# LRFDMDM register map
Vendor: Texas Instruments
Registers are 32-bit, access per field, reset 0x0 unless marked. A register's access mark holds for its fields unless they carry their own. Offsets are as the file gives them; [hi:lo] are bit positions; {n}, {i} and the like mark numbered series; 'fields as' and 'values as' point back to an identical list.

## LRFDMDM (part 2 of 2)
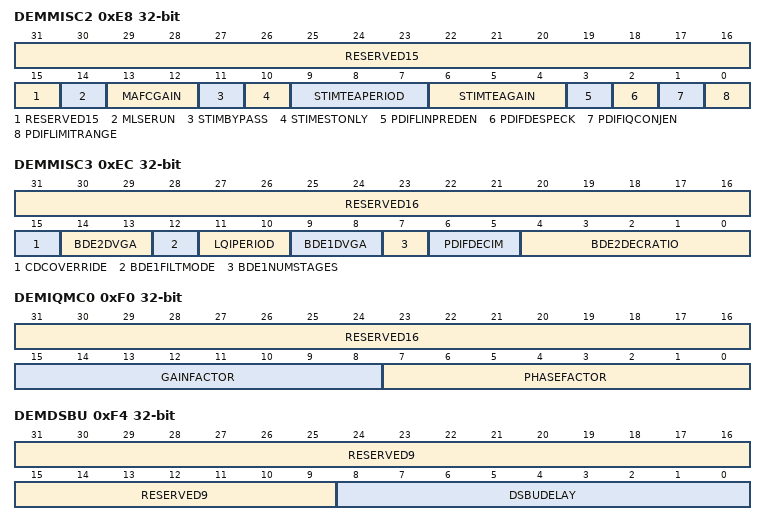
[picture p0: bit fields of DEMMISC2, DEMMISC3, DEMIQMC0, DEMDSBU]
0xE8 DEMMISC2 — Internal. Only to be used through TI provided API.
  [31:15] RESERVED15 ro — Internal. Only to be used through TI provided API.
  [14] MLSERUN rw — Internal. Only to be used through TI provided API.
    1=EN (Internal. Only to be used through TI provided API.); 0=DIS (Internal. Only to be used through TI provided API.)
  [13:12] MAFCGAIN rw — Internal. Only to be used through TI provided API.
    3=ALLONES (Internal. Only to be used through TI provided API.); 0=ALLZEROS (Internal. Only to be used through TI provided API.)
  [11] STIMBYPASS rw — Internal. Only to be used through TI provided API.
    values as MLSERUN
  [10] STIMESTONLY rw — Internal. Only to be used through TI provided API.
    values as MLSERUN
  [9:7] STIMTEAPERIOD rw — Internal. Only to be used through TI provided API.
    5=SYM128 (Internal. Only to be used through TI provided API.); 4=SYM64 (Internal. Only to be used through TI provided API.); 3=SYM32 (Internal. Only to be used through TI provided API.); 2=SYM16 (Internal. Only to be used through TI provided API.); 1=SYM8 (Internal. Only to be used through TI provided API.); 0=SYM4 (Internal. Only to be used through TI provided API.)
  [6:4] STIMTEAGAIN rw — Internal. Only to be used through TI provided API.
    7=DIV4 (Internal. Only to be used through TI provided API.); 6=DIV8 (Internal. Only to be used through TI provided API.); 5=DIV16 (Internal. Only to be used through TI provided API.); 4=DIV32 (Internal. Only to be used through TI provided API.); 3=DIV64 (Internal. Only to be used through TI provided API.); 2=DIV128 (Internal. Only to be used through TI provided API.); 1=DIV256 (Internal. Only to be used through TI provided API.); 0=DIV512 (Internal. Only to be used through TI provided API.)
  [3] PDIFLINPREDEN rw — Internal. Only to be used through TI provided API.
    1=ON (Internal. Only to be used through TI provided API.); 0=OFF (Internal. Only to be used through TI provided API.)
  [2] PDIFDESPECK rw — Internal. Only to be used through TI provided API.
    values as MLSERUN
  [1] PDIFIQCONJEN rw — Internal. Only to be used through TI provided API.
    values as PDIFLINPREDEN
  [0] PDIFLIMITRANGE rw — Internal. Only to be used through TI provided API.
    values as MLSERUN
0xEC DEMMISC3 — Internal. Only to be used through TI provided API.
  [31:16] RESERVED16 ro — Internal. Only to be used through TI provided API.
  [15] CDCOVERRIDE rw — Internal. Only to be used through TI provided API.
  [14:13] BDE2DVGA rw — Internal. Only to be used through TI provided API.
    3=GAIN8 (Internal. Only to be used through TI provided API.); 2=GAIN4 (Internal. Only to be used through TI provided API.); 1=GAIN2 (Internal. Only to be used through TI provided API.); 0=GAIN1 (Internal. Only to be used through TI provided API.)
  [12] BDE1FILTMODE rw — Internal. Only to be used through TI provided API.
    1=DIV2 (Internal. Only to be used through TI provided API.); 0=DIV1 (Internal. Only to be used through TI provided API.)
  [11:10] LQIPERIOD rw — Internal. Only to be used through TI provided API.
    3=SYM1024 (Internal. Only to be used through TI provided API.); 2=SYM256 (Internal. Only to be used through TI provided API.); 1=SYM64 (Internal. Only to be used through TI provided API.); 0=SYM16 (Internal. Only to be used through TI provided API.)
  [9:8] BDE1DVGA rw — Internal. Only to be used through TI provided API.
    values as BDE2DVGA
  [7] BDE1NUMSTAGES rw — Internal. Only to be used through TI provided API.
    values as BDE1FILTMODE
  [6:5] PDIFDECIM rw — Internal. Only to be used through TI provided API.
    2=DIV4 (Internal. Only to be used through TI provided API.); 1=DIV2 (Internal. Only to be used through TI provided API.); 0=DIV1 (Internal. Only to be used through TI provided API.)
  [4:0] BDE2DECRATIO rw — Internal. Only to be used through TI provided API.
    3=DIV8 (Internal. Only to be used through TI provided API.); 2=DIV4 (Internal. Only to be used through TI provided API.); 1=DIV2 (Internal. Only to be used through TI provided API.); 0=DIV1 (Internal. Only to be used through TI provided API.)
0xF0 DEMIQMC0 — Internal. Only to be used through TI provided API.
  [31:16] RESERVED16 ro — Internal. Only to be used through TI provided API.
  [15:8] GAINFACTOR rw — Internal. Only to be used through TI provided API.
    255=ALLONES (Internal. Only to be used through TI provided API.); 0=ALLZEROS (Internal. Only to be used through TI provided API.)
  [7:0] PHASEFACTOR rw — Internal. Only to be used through TI provided API.
    values as GAINFACTOR
0xF4 DEMDSBU — Internal. Only to be used through TI provided API.
  [31:9] RESERVED9 ro — Internal. Only to be used through TI provided API.
  [8:0] DSBUDELAY rw — Internal. Only to be used through TI provided API.
    values as DEMIQMC0.GAINFACTOR
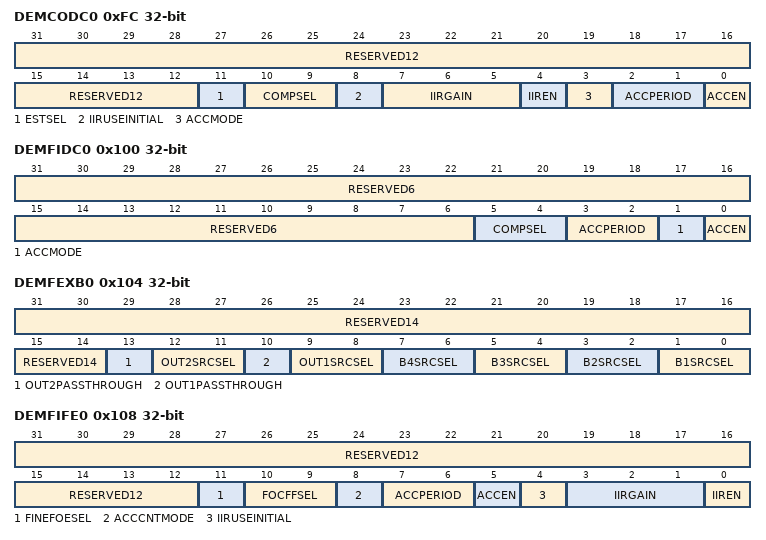
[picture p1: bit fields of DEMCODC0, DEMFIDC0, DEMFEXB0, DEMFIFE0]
0xFC DEMCODC0 — Internal. Only to be used through TI provided API.
  [31:12] RESERVED12 ro — Internal. Only to be used through TI provided API.
  [11] ESTSEL rw — Internal. Only to be used through TI provided API.
    1=IIR (Internal. Only to be used through TI provided API.); 0=ACC (Internal. Only to be used through TI provided API.)
  [10:9] COMPSEL rw — Internal. Only to be used through TI provided API.
    3=IIR (Internal. Only to be used through TI provided API.); 2=ACC (Internal. Only to be used through TI provided API.); 0=MANUAL (Internal. Only to be used through TI provided API.)
  [8] IIRUSEINITIAL rw — Internal. Only to be used through TI provided API.
    values as DEMMISC2.MLSERUN
  [7:5] IIRGAIN rw — Internal. Only to be used through TI provided API.
    7=DIV1024 (Internal. Only to be used through TI provided API.); 6=DIV512 (Internal. Only to be used through TI provided API.); 5=DIV256 (Internal. Only to be used through TI provided API.); 4=DIV128 (Internal. Only to be used through TI provided API.); 3=DIV64 (Internal. Only to be used through TI provided API.); 2=DIV32 (Internal. Only to be used through TI provided API.); 1=DIV16 (Internal. Only to be used through TI provided API.); 0=OFF (Internal. Only to be used through TI provided API.)
  [4] IIREN rw — Internal. Only to be used through TI provided API.
    values as DEMMISC2.PDIFLINPREDEN
  [3] ACCMODE rw — Internal. Only to be used through TI provided API.
    1=CONT (Internal. Only to be used through TI provided API.); 0=SINGLE (Internal. Only to be used through TI provided API.)
  [2:1] ACCPERIOD rw — Internal. Only to be used through TI provided API.
    3=SMPL512 (Internal. Only to be used through TI provided API.); 2=SMPL128 (Internal. Only to be used through TI provided API.); 1=SMPL32 (Internal. Only to be used through TI provided API.); 0=SMPL8 (Internal. Only to be used through TI provided API.)
  [0] ACCEN rw — Internal. Only to be used through TI provided API.
    values as DEMMISC2.PDIFLINPREDEN
0x100 DEMFIDC0 — Internal. Only to be used through TI provided API.
  [31:6] RESERVED6 ro — Internal. Only to be used through TI provided API.
  [5:4] COMPSEL rw — Internal. Only to be used through TI provided API.
    2=ACC (Internal. Only to be used through TI provided API.); 0=MANUAL (Internal. Only to be used through TI provided API.)
  [3:2] ACCPERIOD rw — Internal. Only to be used through TI provided API.
    values as DEMCODC0.ACCPERIOD
  [1] ACCMODE rw — Internal. Only to be used through TI provided API.
    values as DEMCODC0.ACCMODE
  [0] ACCEN rw — Internal. Only to be used through TI provided API.
    values as DEMMISC2.PDIFLINPREDEN
0x104 DEMFEXB0 — Internal. Only to be used through TI provided API.
  [31:14] RESERVED14 ro — Internal. Only to be used through TI provided API.
  [13] OUT2PASSTHROUGH rw — Internal. Only to be used through TI provided API.
    1=ONE (Internal. Only to be used through TI provided API.); 0=ZERO (Internal. Only to be used through TI provided API.)
  [12:11] OUT2SRCSEL rw — Internal. Only to be used through TI provided API.
    2=BDE1 (Internal. Only to be used through TI provided API.); 1=CMIX (Internal. Only to be used through TI provided API.); 0=CODC (Internal. Only to be used through TI provided API.)
  [10] OUT1PASSTHROUGH rw — Internal. Only to be used through TI provided API.
    values as OUT2PASSTHROUGH
  [9:8] OUT1SRCSEL rw — Internal. Only to be used through TI provided API.
    values as OUT2SRCSEL
  [7:6] B4SRCSEL rw — Internal. Only to be used through TI provided API.
    3=ONES (Internal. Only to be used through TI provided API.); 0=ZEROS (Internal. Only to be used through TI provided API.)
  [5:4] B3SRCSEL rw — Internal. Only to be used through TI provided API.
    2=CMIX (Internal. Only to be used through TI provided API.); 1=CODC (Internal. Only to be used through TI provided API.); 0=INPUT (Internal. Only to be used through TI provided API.)
  [3:2] B2SRCSEL rw — Internal. Only to be used through TI provided API.
    2=BDE1 (Internal. Only to be used through TI provided API.); 1=CODC (Internal. Only to be used through TI provided API.); 0=INPUT (Internal. Only to be used through TI provided API.)
  [1:0] B1SRCSEL rw — Internal. Only to be used through TI provided API.
    2=BDE1 (Internal. Only to be used through TI provided API.); 1=CMIX (Internal. Only to be used through TI provided API.); 0=INPUT (Internal. Only to be used through TI provided API.)
0x108 DEMFIFE0 — Internal. Only to be used through TI provided API.
  [31:12] RESERVED12 ro — Internal. Only to be used through TI provided API.
  [11] FINEFOESEL rw — Internal. Only to be used through TI provided API.
    1=ACC (Internal. Only to be used through TI provided API.); 0=IIR (Internal. Only to be used through TI provided API.)
  [10:9] FOCFFSEL rw — Internal. Only to be used through TI provided API.
    2=MANUAL (Internal. Only to be used through TI provided API.); 1=ACC (Internal. Only to be used through TI provided API.); 0=IIR (Internal. Only to be used through TI provided API.)
  [8] ACCCNTMODE rw — Internal. Only to be used through TI provided API.
    values as DEMCODC0.ACCMODE
  [7:6] ACCPERIOD rw — Internal. Only to be used through TI provided API.
    3=PER512 (Internal. Only to be used through TI provided API.); 2=PER256 (Internal. Only to be used through TI provided API.); 1=PER128 (Internal. Only to be used through TI provided API.); 0=PER64 (Internal. Only to be used through TI provided API.)
  [5] ACCEN rw — Internal. Only to be used through TI provided API.
    values as DEMMISC2.PDIFLINPREDEN
  [4] IIRUSEINITIAL rw — Internal. Only to be used through TI provided API.
    values as DEMMISC2.MLSERUN
  [3:1] IIRGAIN rw — Internal. Only to be used through TI provided API.
    values as DEMCODC0.IIRGAIN
  [0] IIREN rw — Internal. Only to be used through TI provided API.
    values as DEMMISC2.PDIFLINPREDEN
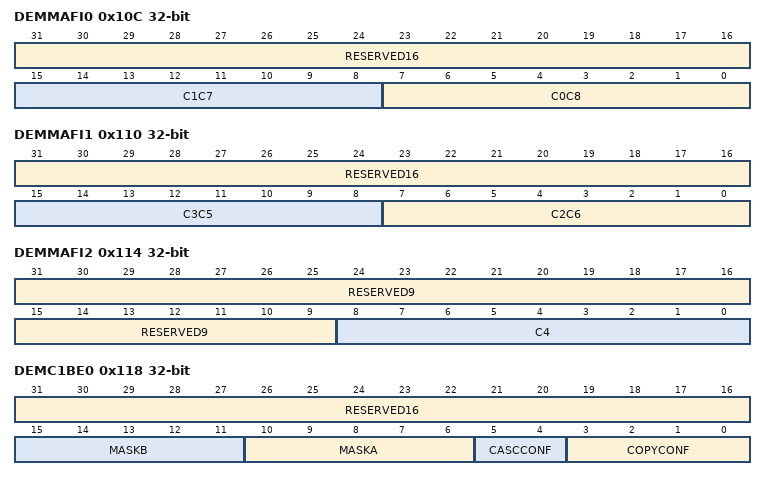
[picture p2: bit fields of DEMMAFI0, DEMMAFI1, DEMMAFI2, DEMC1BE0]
0x10C DEMMAFI0 — Internal. Only to be used through TI provided API.
  [31:16] RESERVED16 ro — Internal. Only to be used through TI provided API.
  [15:8] C1C7 rw — Internal. Only to be used through TI provided API.
    values as DEMIQMC0.GAINFACTOR
  [7:0] C0C8 rw — Internal. Only to be used through TI provided API.
    values as DEMIQMC0.GAINFACTOR
0x110 DEMMAFI1 — Internal. Only to be used through TI provided API.
  [31:16] RESERVED16 ro — Internal. Only to be used through TI provided API.
  [15:8] C3C5 rw — Internal. Only to be used through TI provided API.
    values as DEMIQMC0.GAINFACTOR
  [7:0] C2C6 rw — Internal. Only to be used through TI provided API.
    values as DEMIQMC0.GAINFACTOR
0x114 DEMMAFI2 — Internal. Only to be used through TI provided API.
  [31:9] RESERVED9 ro — Internal. Only to be used through TI provided API.
  [8:0] C4 rw — Internal. Only to be used through TI provided API.
    0x1FF=ALLONES (Internal. Only to be used through TI provided API.); 0=ALLZEROS (Internal. Only to be used through TI provided API.)
0x118 DEMC1BE0 — Internal. Only to be used through TI provided API.
  [31:16] RESERVED16 ro — Internal. Only to be used through TI provided API.
  [15:11] MASKB rw — Internal. Only to be used through TI provided API.
    31=ALLONES (Internal. Only to be used through TI provided API.); 0=ALLZEROS (Internal. Only to be used through TI provided API.)
  [10:6] MASKA rw — Internal. Only to be used through TI provided API.
    values as MASKB
  [5:4] CASCCONF rw — Internal. Only to be used through TI provided API.
    2=PARALLEL (Internal. Only to be used through TI provided API.); 1=SERIAL (Internal. Only to be used through TI provided API.); 0=SINGLE (Internal. Only to be used through TI provided API.)
  [3:0] COPYCONF rw — Internal. Only to be used through TI provided API.
    15=ALLONES (Internal. Only to be used through TI provided API.); 0=ALLZEROS (Internal. Only to be used through TI provided API.)
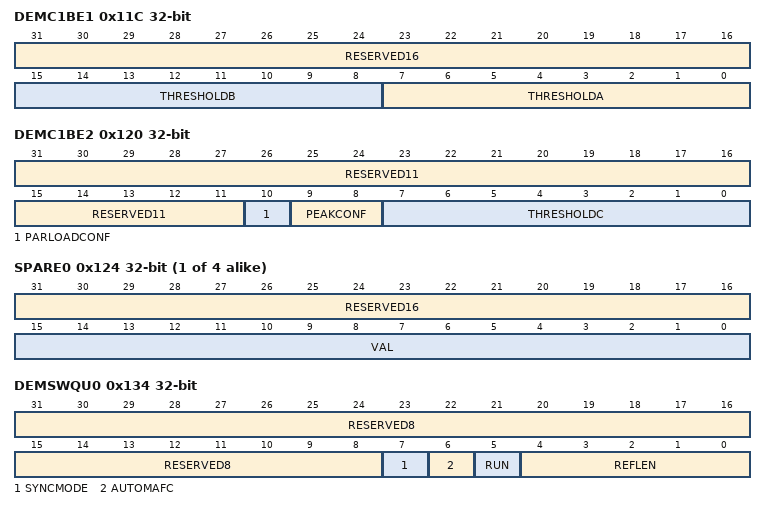
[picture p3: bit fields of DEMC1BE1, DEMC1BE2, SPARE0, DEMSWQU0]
0x11C DEMC1BE1 — Internal. Only to be used through TI provided API.
  [31:16] RESERVED16 ro — Internal. Only to be used through TI provided API.
  [15:8] THRESHOLDB rw — Internal. Only to be used through TI provided API.
    values as DEMIQMC0.GAINFACTOR
  [7:0] THRESHOLDA rw — Internal. Only to be used through TI provided API.
    values as DEMIQMC0.GAINFACTOR
0x120 DEMC1BE2 — Internal. Only to be used through TI provided API.
  [31:11] RESERVED11 ro — Internal. Only to be used through TI provided API.
  [10] PARLOADCONF rw — Internal. Only to be used through TI provided API.
    1=ATOD (Internal. Only to be used through TI provided API.); 0=ATOB (Internal. Only to be used through TI provided API.)
  [9:8] PEAKCONF rw — Internal. Only to be used through TI provided API.
    2=BESTAB (Internal. Only to be used through TI provided API.); 1=BEST (Internal. Only to be used through TI provided API.); 0=THRESH (Internal. Only to be used through TI provided API.)
  [7:0] THRESHOLDC rw — Internal. Only to be used through TI provided API.
    values as DEMIQMC0.GAINFACTOR
{0x124+4i} SPARE{i} (i=0..3) — Internal. Only to be used through TI provided API.
  [31:16] RESERVED16 ro — Internal. Only to be used through TI provided API.
  [15:0] VAL rw — Internal. Only to be used through TI provided API.
    0xFFFF=ALLONES (Internal. Only to be used through TI provided API.); 0=ALLZEROS (Internal. Only to be used through TI provided API.)
0x134 DEMSWQU0 — Internal. Only to be used through TI provided API.
  [31:8] RESERVED8 ro — Internal. Only to be used through TI provided API.
  [7] SYNCMODE rw — Internal. Only to be used through TI provided API.
    values as DEMFEXB0.OUT2PASSTHROUGH
  [6] AUTOMAFC rw — Internal. Only to be used through TI provided API.
    values as DEMMISC2.PDIFLINPREDEN
  [5] RUN rw — Internal. Only to be used through TI provided API.
    values as DEMMISC2.PDIFLINPREDEN
  [4:0] REFLEN rw — Internal. Only to be used through TI provided API.
    values as DEMC1BE0.MASKB
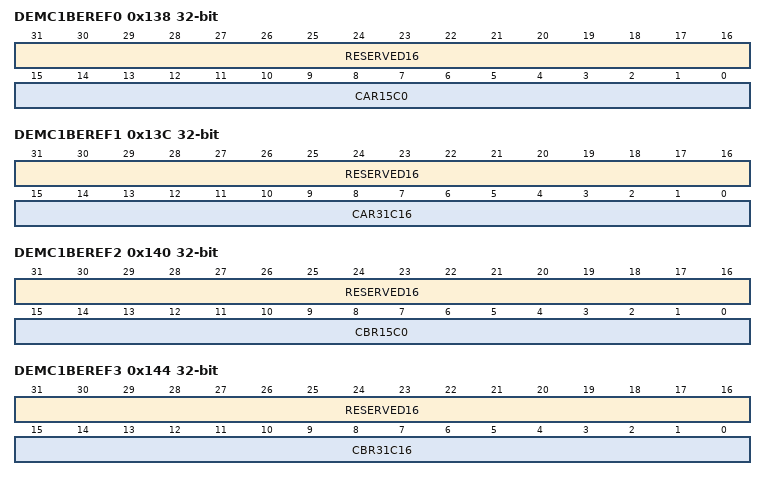
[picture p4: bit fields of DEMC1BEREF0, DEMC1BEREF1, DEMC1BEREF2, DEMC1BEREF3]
0x138 DEMC1BEREF0 — Internal. Only to be used through TI provided API.
  [31:16] RESERVED16 ro — Internal. Only to be used through TI provided API.
  [15:0] CAR15C0 rw — Internal. Only to be used through TI provided API.
    values as SPARE0.VAL
0x13C DEMC1BEREF1 — Internal. Only to be used through TI provided API.
  [31:16] RESERVED16 ro — Internal. Only to be used through TI provided API.
  [15:0] CAR31C16 rw — Internal. Only to be used through TI provided API.
    values as SPARE0.VAL
0x140 DEMC1BEREF2 — Internal. Only to be used through TI provided API.
  [31:16] RESERVED16 ro — Internal. Only to be used through TI provided API.
  [15:0] CBR15C0 rw — Internal. Only to be used through TI provided API.
    values as SPARE0.VAL
0x144 DEMC1BEREF3 — Internal. Only to be used through TI provided API.
  [31:16] RESERVED16 ro — Internal. Only to be used through TI provided API.
  [15:0] CBR31C16 rw — Internal. Only to be used through TI provided API.
    values as SPARE0.VAL
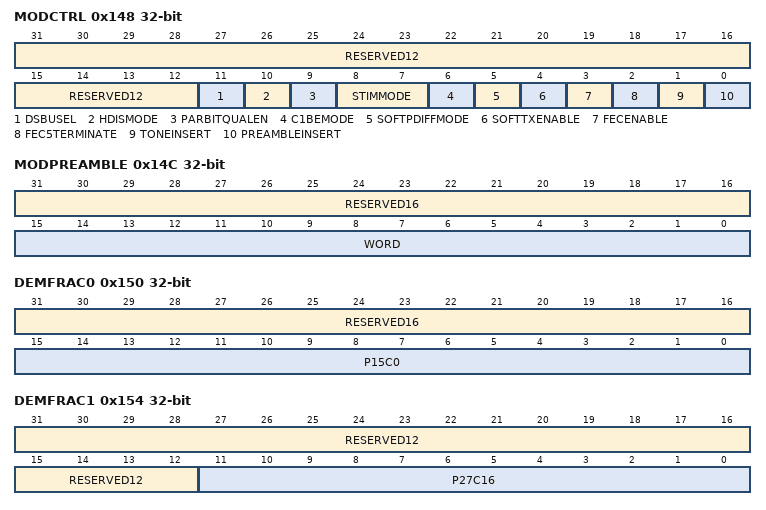
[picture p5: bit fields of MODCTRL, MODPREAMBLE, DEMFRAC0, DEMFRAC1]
0x148 MODCTRL — Internal. Only to be used through TI provided API.
  [31:12] RESERVED12 ro — Internal. Only to be used through TI provided API.
  [11] DSBUSEL rw — Internal. Only to be used through TI provided API.
    values as DEMFEXB0.OUT2PASSTHROUGH
  [10] HDISMODE rw — Internal. Only to be used through TI provided API.
    values as DEMMISC2.MLSERUN
  [9] PARBITQUALEN rw — Internal. Only to be used through TI provided API.
    values as DEMMISC2.PDIFLINPREDEN
  [8:7] STIMMODE rw — Internal. Only to be used through TI provided API.
    2=EARLY (Internal. Only to be used through TI provided API.); 1=LATE (Internal. Only to be used through TI provided API.); 0=NORMAL (Internal. Only to be used through TI provided API.)
  [6] C1BEMODE rw — Internal. Only to be used through TI provided API.
    1=EARLYLATE (Internal. Only to be used through TI provided API.); 0=NORMAL (Internal. Only to be used through TI provided API.)
  [5] SOFTPDIFFMODE rw — Internal. Only to be used through TI provided API.
    values as DEMMISC2.MLSERUN
  [4] SOFTTXENABLE rw — Internal. Only to be used through TI provided API.
    values as DEMMISC2.PDIFLINPREDEN
  [3] FECENABLE rw — Internal. Only to be used through TI provided API.
    values as DEMMISC2.PDIFLINPREDEN
  [2] FEC5TERMINATE rw — Internal. Only to be used through TI provided API.
    values as DEMMISC2.PDIFLINPREDEN
  [1] TONEINSERT rw — Internal. Only to be used through TI provided API.
    values as DEMMISC2.MLSERUN
  [0] PREAMBLEINSERT rw — Internal. Only to be used through TI provided API.
    values as DEMMISC2.MLSERUN
0x14C MODPREAMBLE — Internal. Only to be used through TI provided API.
  [31:16] RESERVED16 ro — Internal. Only to be used through TI provided API.
  [15:0] WORD rw — Internal. Only to be used through TI provided API.
    values as SPARE0.VAL
0x150 DEMFRAC0 — Internal. Only to be used through TI provided API.
  [31:16] RESERVED16 ro — Internal. Only to be used through TI provided API.
  [15:0] P15C0 rw — Internal. Only to be used through TI provided API.
    values as SPARE0.VAL
0x154 DEMFRAC1 — Internal. Only to be used through TI provided API.
  [31:12] RESERVED12 ro — Internal. Only to be used through TI provided API.
  [11:0] P27C16 rw — Internal. Only to be used through TI provided API.
    0xFFF=ALLONES (Internal. Only to be used through TI provided API.); 0=ALLZEROS (Internal. Only to be used through TI provided API.)
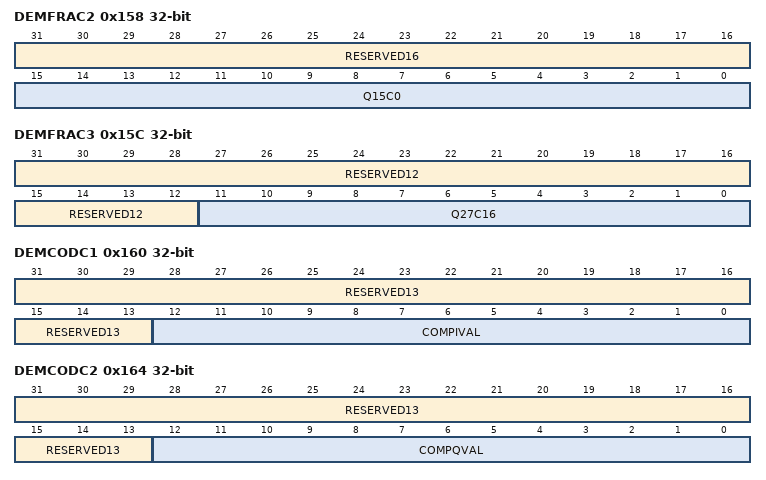
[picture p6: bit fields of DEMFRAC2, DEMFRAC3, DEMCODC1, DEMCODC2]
0x158 DEMFRAC2 — Internal. Only to be used through TI provided API.
  [31:16] RESERVED16 ro — Internal. Only to be used through TI provided API.
  [15:0] Q15C0 rw — Internal. Only to be used through TI provided API.
    values as SPARE0.VAL
0x15C DEMFRAC3 — Internal. Only to be used through TI provided API.
  [31:12] RESERVED12 ro — Internal. Only to be used through TI provided API.
  [11:0] Q27C16 rw — Internal. Only to be used through TI provided API.
    values as DEMFRAC1.P27C16
0x160 DEMCODC1 — Internal. Only to be used through TI provided API.
  [31:13] RESERVED13 ro — Internal. Only to be used through TI provided API.
  [12:0] COMPIVAL rw — Internal. Only to be used through TI provided API.
    0x1FFF=ALLONES (Internal. Only to be used through TI provided API.); 0=ALLZEROS (Internal. Only to be used through TI provided API.)
0x164 DEMCODC2 — Internal. Only to be used through TI provided API.
  [31:13] RESERVED13 ro — Internal. Only to be used through TI provided API.
  [12:0] COMPQVAL rw — Internal. Only to be used through TI provided API.
    values as DEMCODC1.COMPIVAL
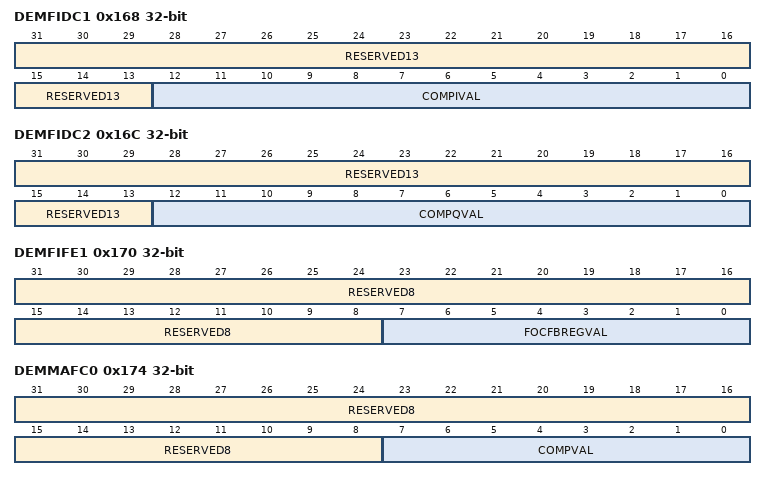
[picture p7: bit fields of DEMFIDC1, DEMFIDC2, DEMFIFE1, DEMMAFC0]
0x168 DEMFIDC1 — Internal. Only to be used through TI provided API.
  fields as DEMCODC1
0x16C DEMFIDC2 — Internal. Only to be used through TI provided API.
  fields as DEMCODC2
0x170 DEMFIFE1 — Internal. Only to be used through TI provided API.
  [31:8] RESERVED8 ro — Internal. Only to be used through TI provided API.
  [7:0] FOCFBREGVAL rw — Internal. Only to be used through TI provided API.
    values as DEMIQMC0.GAINFACTOR
0x174 DEMMAFC0 — Internal. Only to be used through TI provided API.
  [31:8] RESERVED8 ro — Internal. Only to be used through TI provided API.
  [7:0] COMPVAL rw — Internal. Only to be used through TI provided API.
    values as DEMIQMC0.GAINFACTOR
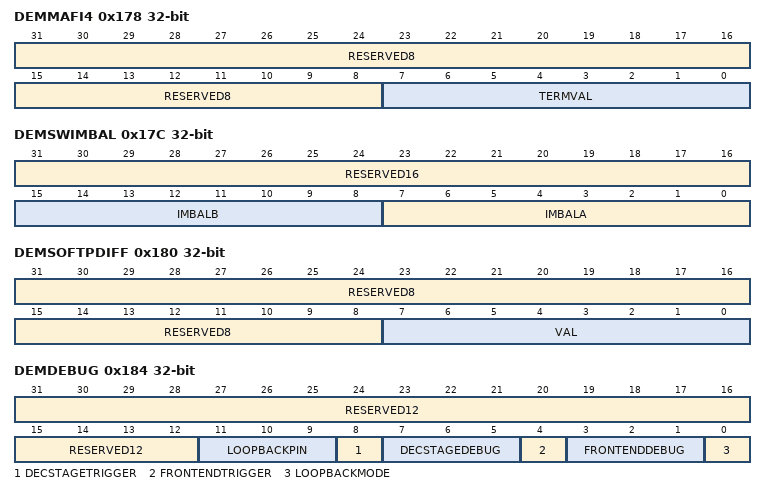
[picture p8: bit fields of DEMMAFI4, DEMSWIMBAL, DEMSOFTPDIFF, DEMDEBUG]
0x178 DEMMAFI4 — Internal. Only to be used through TI provided API.
  [31:8] RESERVED8 ro — Internal. Only to be used through TI provided API.
  [7:0] TERMVAL rw — Internal. Only to be used through TI provided API.
    values as DEMIQMC0.GAINFACTOR
0x17C DEMSWIMBAL — Internal. Only to be used through TI provided API.
  [31:16] RESERVED16 ro — Internal. Only to be used through TI provided API.
  [15:8] IMBALB rw — Internal. Only to be used through TI provided API.
    values as DEMIQMC0.GAINFACTOR
  [7:0] IMBALA rw — Internal. Only to be used through TI provided API.
    values as DEMIQMC0.GAINFACTOR
0x180 DEMSOFTPDIFF — Internal. Only to be used through TI provided API.
  [31:8] RESERVED8 ro — Internal. Only to be used through TI provided API.
  [7:0] VAL rw — Internal. Only to be used through TI provided API.
    values as DEMIQMC0.GAINFACTOR
0x184 DEMDEBUG — Internal. Only to be used through TI provided API.
  [31:12] RESERVED12 ro — Internal. Only to be used through TI provided API.
  [11:9] LOOPBACKPIN rw — Internal. Only to be used through TI provided API.
    {v}=GPI{v} (Internal. Only to be used through TI provided API.) (v=0..7)
  [8] DECSTAGETRIGGER rw — Internal. Only to be used through TI provided API.
    values as DEMFEXB0.OUT2PASSTHROUGH
  [7:5] DECSTAGEDEBUG rw — Internal. Only to be used through TI provided API.
    7=SOFD (Internal. Only to be used through TI provided API.); 6=STIM (Internal. Only to be used through TI provided API.); 5=MAFC (Internal. Only to be used through TI provided API.); 4=C1BE (Internal. Only to be used through TI provided API.); 3=MAFI (Internal. Only to be used through TI provided API.); 2=FIFE (Internal. Only to be used through TI provided API.); 1=PDIF (Internal. Only to be used through TI provided API.); 0=NOSEL (Internal. Only to be used through TI provided API.)
  [4] FRONTENDTRIGGER rw — Internal. Only to be used through TI provided API.
    values as DEMFEXB0.OUT2PASSTHROUGH
  [3:1] FRONTENDDEBUG rw — Internal. Only to be used through TI provided API.
    7=FIDC (Internal. Only to be used through TI provided API.); 6=FRAC (Internal. Only to be used through TI provided API.); 5=CHFI (Internal. Only to be used through TI provided API.); 4=BDE2 (Internal. Only to be used through TI provided API.); 3=FEXB2 (Internal. Only to be used through TI provided API.); 2=BDE1 (Internal. Only to be used through TI provided API.); 1=IQMC (Internal. Only to be used through TI provided API.); 0=NOSEL (Internal. Only to be used through TI provided API.)
  [0] LOOPBACKMODE rw — Internal. Only to be used through TI provided API.
    values as DEMFEXB0.OUT2PASSTHROUGH
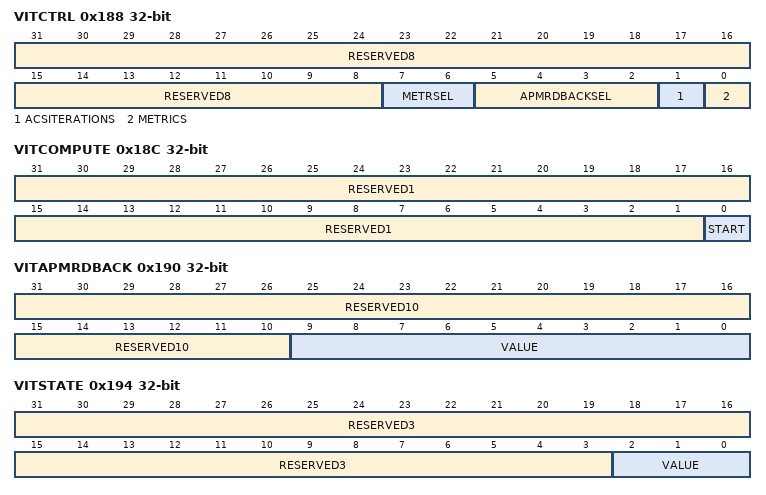
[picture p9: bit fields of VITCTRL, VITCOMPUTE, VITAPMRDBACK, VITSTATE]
0x188 VITCTRL — Internal. Only to be used through TI provided API.
  [31:8] RESERVED8 ro — Internal. Only to be used through TI provided API.
  [7:6] METRSEL rw — Internal. Only to be used through TI provided API.
    3=MLSE (Internal. Only to be used through TI provided API.); 2=SOFD (Internal. Only to be used through TI provided API.); 1=PHAC (Internal. Only to be used through TI provided API.); 0=MET5M (Internal. Only to be used through TI provided API.)
  [5:2] APMRDBACKSEL rw — Internal. Only to be used through TI provided API.
    {v}=APM{v-8} (Internal. Only to be used through TI provided API.) (v=8..15); 0=NOSEL (Internal. Only to be used through TI provided API.)
  [1] ACSITERATIONS rw — Internal. Only to be used through TI provided API.
    1=CODE23 (Internal. Only to be used through TI provided API.); 0=CODE12 (Internal. Only to be used through TI provided API.)
  [0] METRICS rw — Internal. Only to be used through TI provided API.
    1=SOFT (Internal. Only to be used through TI provided API.); 0=HW (Internal. Only to be used through TI provided API.)
0x18C VITCOMPUTE — Internal. Only to be used through TI provided API.
  [31:1] RESERVED1 ro — Internal. Only to be used through TI provided API.
  [0] START wo — Internal. Only to be used through TI provided API.
    values as DEMFEXB0.OUT2PASSTHROUGH
0x190 VITAPMRDBACK ro — Internal. Only to be used through TI provided API.
  [31:10] RESERVED10 — Internal. Only to be used through TI provided API.
  [9:0] VALUE — Internal. Only to be used through TI provided API.
    0x3FF=ALLONES (Internal. Only to be used through TI provided API.); 0=ALLZEROS (Internal. Only to be used through TI provided API.)
0x194 VITSTATE ro — Internal. Only to be used through TI provided API.
  [31:3] RESERVED3 — Internal. Only to be used through TI provided API.
  [2:0] VALUE — Internal. Only to be used through TI provided API.
    7=ALLONES (Internal. Only to be used through TI provided API.); 0=ALLZEROS (Internal. Only to be used through TI provided API.)
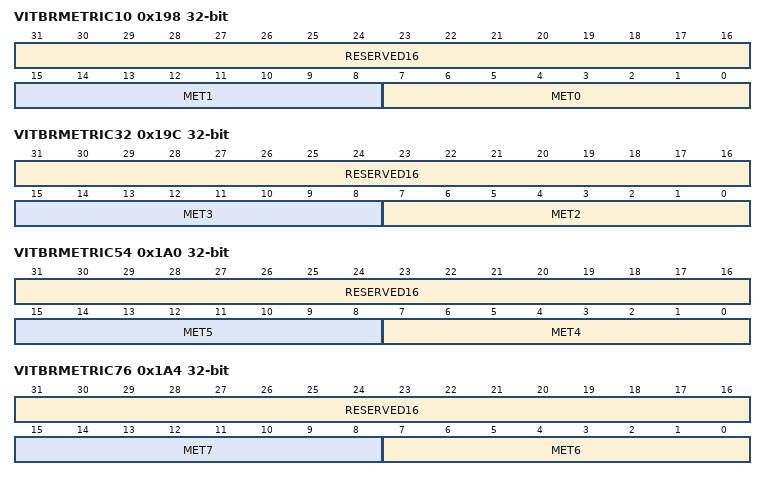
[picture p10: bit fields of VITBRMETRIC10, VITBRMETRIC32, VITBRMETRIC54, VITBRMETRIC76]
0x198 VITBRMETRIC10 — Internal. Only to be used through TI provided API.
  [31:16] RESERVED16 ro — Internal. Only to be used through TI provided API.
  [15:8] MET1 rw — Internal. Only to be used through TI provided API.
    values as DEMIQMC0.GAINFACTOR
  [7:0] MET0 rw — Internal. Only to be used through TI provided API.
    values as DEMIQMC0.GAINFACTOR
0x19C VITBRMETRIC32 — Internal. Only to be used through TI provided API.
  [31:16] RESERVED16 ro — Internal. Only to be used through TI provided API.
  [15:8] MET3 rw — Internal. Only to be used through TI provided API.
    values as DEMIQMC0.GAINFACTOR
  [7:0] MET2 rw — Internal. Only to be used through TI provided API.
    values as DEMIQMC0.GAINFACTOR
0x1A0 VITBRMETRIC54 — Internal. Only to be used through TI provided API.
  [31:16] RESERVED16 ro — Internal. Only to be used through TI provided API.
  [15:8] MET5 rw — Internal. Only to be used through TI provided API.
    values as DEMIQMC0.GAINFACTOR
  [7:0] MET4 rw — Internal. Only to be used through TI provided API.
    values as DEMIQMC0.GAINFACTOR
0x1A4 VITBRMETRIC76 — Internal. Only to be used through TI provided API.
  [31:16] RESERVED16 ro — Internal. Only to be used through TI provided API.
  [15:8] MET7 rw — Internal. Only to be used through TI provided API.
    values as DEMIQMC0.GAINFACTOR
  [7:0] MET6 rw — Internal. Only to be used through TI provided API.
    values as DEMIQMC0.GAINFACTOR
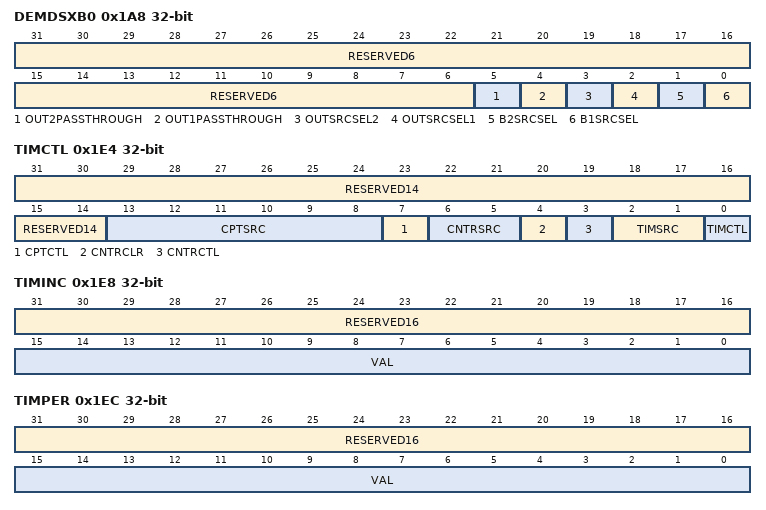
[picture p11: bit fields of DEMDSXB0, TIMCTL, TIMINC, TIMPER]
0x1A8 DEMDSXB0 — Internal. Only to be used through TI provided API.
  [31:6] RESERVED6 ro — Internal. Only to be used through TI provided API.
  [5] OUT2PASSTHROUGH rw — Internal. Only to be used through TI provided API.
    values as DEMFEXB0.OUT2PASSTHROUGH
  [4] OUT1PASSTHROUGH rw — Internal. Only to be used through TI provided API.
    values as DEMFEXB0.OUT2PASSTHROUGH
  [3] OUTSRCSEL2 rw — Internal. Only to be used through TI provided API.
    1=MAFI (Internal. Only to be used through TI provided API.); 0=FIFE (Internal. Only to be used through TI provided API.)
  [2] OUTSRCSEL1 rw — Internal. Only to be used through TI provided API.
    values as OUTSRCSEL2
  [1] B2SRCSEL rw — Internal. Only to be used through TI provided API.
    1=FIFE (Internal. Only to be used through TI provided API.); 0=INPUT (Internal. Only to be used through TI provided API.)
  [0] B1SRCSEL rw — Internal. Only to be used through TI provided API.
    1=MAFI (Internal. Only to be used through TI provided API.); 0=INPUT (Internal. Only to be used through TI provided API.)
0x1E4 TIMCTL — Internal. Only to be used through TI provided API.
  [31:14] RESERVED14 ro — Internal. Only to be used through TI provided API.
  [13:8] CPTSRC rw — Internal. Only to be used through TI provided API.
    63=ALLONES (Internal. Only to be used through TI provided API.); 0=ALLZEROS (Internal. Only to be used through TI provided API.)
  [7] CPTCTL rw — Internal. Only to be used through TI provided API.
    values as DEMMISC2.MLSERUN
  [6:5] CNTRSRC rw — Internal. Only to be used through TI provided API.
    3=CLK4BAUDF (Internal. Only to be used through TI provided API.); 2=CLK4BAUD (Internal. Only to be used through TI provided API.); 1=CLKBAUD (Internal. Only to be used through TI provided API.); 0=CLK (Internal. Only to be used through TI provided API.)
  [4] CNTRCLR rw — Internal. Only to be used through TI provided API.
    values as DEMFEXB0.OUT2PASSTHROUGH
  [3] CNTRCTL rw — Internal. Only to be used through TI provided API.
    values as DEMFEXB0.OUT2PASSTHROUGH
  [2:1] TIMSRC rw — Internal. Only to be used through TI provided API.
    values as CNTRSRC
  [0] TIMCTL rw — Internal. Only to be used through TI provided API.
    values as DEMMISC2.MLSERUN
0x1E8 TIMINC — Internal. Only to be used through TI provided API.
  fields as SPARE0
0x1EC TIMPER — Internal. Only to be used through TI provided API.
  fields as SPARE0
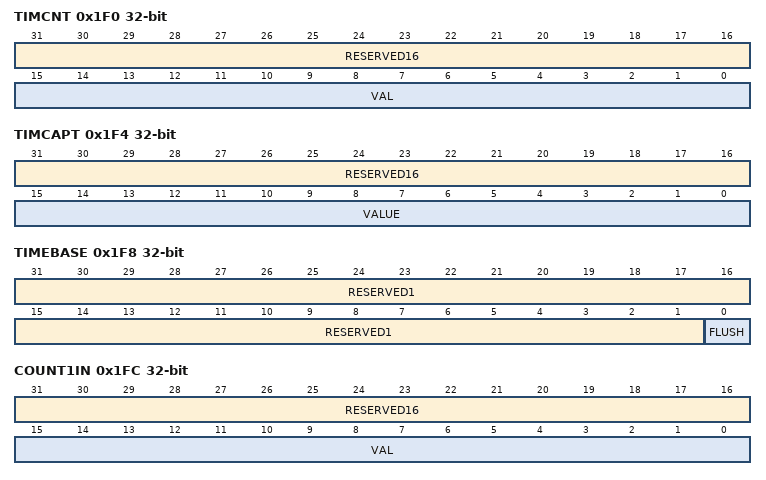
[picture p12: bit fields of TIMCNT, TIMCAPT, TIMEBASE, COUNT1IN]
0x1F0 TIMCNT ro — Internal. Only to be used through TI provided API.
  [31:16] RESERVED16 — Internal. Only to be used through TI provided API.
  [15:0] VAL — Internal. Only to be used through TI provided API.
    values as SPARE0.VAL
0x1F4 TIMCAPT ro — Internal. Only to be used through TI provided API.
  [31:16] RESERVED16 — Internal. Only to be used through TI provided API.
  [15:0] VALUE — Internal. Only to be used through TI provided API.
    values as SPARE0.VAL
0x1F8 TIMEBASE — Internal. Only to be used through TI provided API.
  [31:1] RESERVED1 ro — Internal. Only to be used through TI provided API.
  [0] FLUSH wo — Internal. Only to be used through TI provided API.
    values as DEMFEXB0.OUT2PASSTHROUGH
0x1FC COUNT1IN — Internal. Only to be used through TI provided API.
  fields as SPARE0
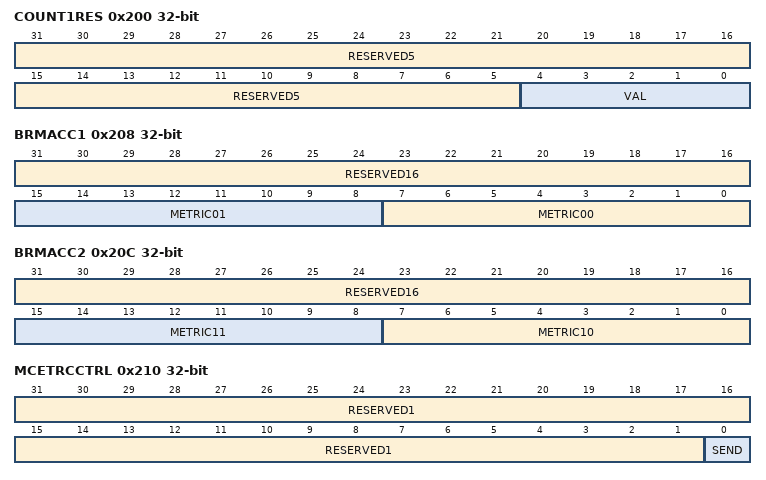
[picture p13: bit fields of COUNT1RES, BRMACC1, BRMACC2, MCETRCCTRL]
0x200 COUNT1RES ro — Internal. Only to be used through TI provided API.
  [31:5] RESERVED5 — Internal. Only to be used through TI provided API.
  [4:0] VAL — Internal. Only to be used through TI provided API.
    values as DEMC1BE0.MASKB
0x208 BRMACC1 ro — Internal. Only to be used through TI provided API.
  [31:16] RESERVED16 — Internal. Only to be used through TI provided API.
  [15:8] METRIC01 — Internal. Only to be used through TI provided API.
    values as DEMIQMC0.GAINFACTOR
  [7:0] METRIC00 — Internal. Only to be used through TI provided API.
    values as DEMIQMC0.GAINFACTOR
0x20C BRMACC2 ro — Internal. Only to be used through TI provided API.
  [31:16] RESERVED16 — Internal. Only to be used through TI provided API.
  [15:8] METRIC11 — Internal. Only to be used through TI provided API.
    values as DEMIQMC0.GAINFACTOR
  [7:0] METRIC10 — Internal. Only to be used through TI provided API.
    values as DEMIQMC0.GAINFACTOR
0x210 MCETRCCTRL — Internal. Only to be used through TI provided API.
  [31:1] RESERVED1 ro — Internal. Only to be used through TI provided API.
  [0] SEND wo — Internal. Only to be used through TI provided API.
    values as DEMFEXB0.OUT2PASSTHROUGH
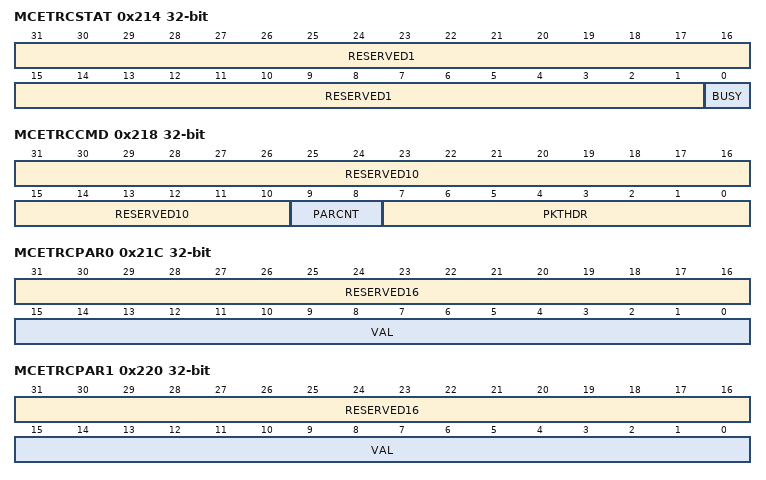
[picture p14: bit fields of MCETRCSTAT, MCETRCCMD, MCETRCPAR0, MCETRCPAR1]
0x214 MCETRCSTAT ro — Internal. Only to be used through TI provided API.
  [31:1] RESERVED1 — Internal. Only to be used through TI provided API.
  [0] BUSY — Internal. Only to be used through TI provided API.
    values as DEMFEXB0.OUT2PASSTHROUGH
0x218 MCETRCCMD — Internal. Only to be used through TI provided API.
  [31:10] RESERVED10 ro — Internal. Only to be used through TI provided API.
  [9:8] PARCNT rw — Internal. Only to be used through TI provided API.
    values as DEMMISC2.MAFCGAIN
  [7:0] PKTHDR rw — Internal. Only to be used through TI provided API.
    values as DEMIQMC0.GAINFACTOR
0x21C MCETRCPAR0 — Internal. Only to be used through TI provided API.
  fields as SPARE0
0x220 MCETRCPAR1 — Internal. Only to be used through TI provided API.
  fields as SPARE0
0x224 RDCAPT0 — Internal. Only to be used through TI provided API.
  [31:6] RESERVED6 ro — Internal. Only to be used through TI provided API.
  [5] CHFI wo — Internal. Only to be used through TI provided API.
    values as DEMFEXB0.OUT2PASSTHROUGH
  [4] BDE2 wo — Internal. Only to be used through TI provided API.
    values as DEMFEXB0.OUT2PASSTHROUGH
  [3] FIDC wo — Internal. Only to be used through TI provided API.
    values as DEMFEXB0.OUT2PASSTHROUGH
  [2] FRAC wo — Internal. Only to be used through TI provided API.
    values as DEMFEXB0.OUT2PASSTHROUGH
  [1] MGEX wo — Internal. Only to be used through TI provided API.
    values as DEMFEXB0.OUT2PASSTHROUGH
  [0] CODC wo — Internal. Only to be used through TI provided API.
    values as DEMFEXB0.OUT2PASSTHROUGH
0x228 RDCAPT1 — Internal. Only to be used through TI provided API.
  [31:14] RESERVED14 ro — Internal. Only to be used through TI provided API.
  [13] COHRX wo — Internal. Only to be used through TI provided API.
    values as DEMFEXB0.OUT2PASSTHROUGH
  [n+9] C1BEX{n} wo (n=0..3) — Internal. Only to be used through TI provided API.
    values as DEMFEXB0.OUT2PASSTHROUGH
  [8] SOFD wo — Internal. Only to be used through TI provided API.
    values as DEMFEXB0.OUT2PASSTHROUGH
  [7] LQIE wo — Internal. Only to be used through TI provided API.
    values as DEMFEXB0.OUT2PASSTHROUGH
  [6] STIM wo — Internal. Only to be used through TI provided API.
    values as DEMFEXB0.OUT2PASSTHROUGH
  [5] FIFE wo — Internal. Only to be used through TI provided API.
    values as DEMFEXB0.OUT2PASSTHROUGH
  [4] PDIF wo — Internal. Only to be used through TI provided API.
    values as DEMFEXB0.OUT2PASSTHROUGH
  [3] CA2P wo — Internal. Only to be used through TI provided API.
    values as DEMFEXB0.OUT2PASSTHROUGH
  [2] MAFI wo — Internal. Only to be used through TI provided API.
    values as DEMFEXB0.OUT2PASSTHROUGH
  [1] DSBU wo — Internal. Only to be used through TI provided API.
    values as DEMFEXB0.OUT2PASSTHROUGH
  [0] MLSEBIT wo — Internal. Only to be used through TI provided API.
    values as DEMFEXB0.OUT2PASSTHROUGH
0x22C FECAPT0 — Internal. Only to be used through TI provided API.
  [31:13] RESERVED13 ro — Internal. Only to be used through TI provided API.
  [12:0] VAL rw — Internal. Only to be used through TI provided API.
    values as DEMCODC1.COMPIVAL
0x230 FECAPT1 — Internal. Only to be used through TI provided API.
  fields as FECAPT0
{0x234+4i} DSCAPT{i} (i=0..3) — Internal. Only to be used through TI provided API.
  fields as DEMSOFTPDIFF
0x244 DEMSWQU1 ro — Internal. Only to be used through TI provided API.
  [31:10] RESERVED10 — Internal. Only to be used through TI provided API.
  [9:2] MAFCCOMPVAL — Internal. Only to be used through TI provided API.
    values as DEMIQMC0.GAINFACTOR
  [1] SWSEL — Internal. Only to be used through TI provided API.
    1=B (Internal. Only to be used through TI provided API.); 0=A (Internal. Only to be used through TI provided API.)
  [0] SYNCED — Internal. Only to be used through TI provided API.
    values as DEMFEXB0.OUT2PASSTHROUGH
0x248 GPOCTRL0 — Internal. Only to be used through TI provided API.
  [31:16] RESERVED16 ro — Internal. Only to be used through TI provided API.
  [15:14] GPO7 rw — Internal. Only to be used through TI provided API.
    3=THREE (Internal. Only to be used through TI provided API.); 2=TWO (Internal. Only to be used through TI provided API.); 1=TOPSM_WAIT (Internal. Only to be used through TI provided API.); 0=SW7 (Internal. Only to be used through TI provided API.)
  [13:12] GPO6 rw — Internal. Only to be used through TI provided API.
    3=THREE (Internal. Only to be used through TI provided API.); 2=TWO (Internal. Only to be used through TI provided API.); 1=TRANSPARENT_OUT (Internal. Only to be used through TI provided API.); 0=SW6 (Internal. Only to be used through TI provided API.)
  [11:10] GPO5 rw — Internal. Only to be used through TI provided API.
    3=THREE (Internal. Only to be used through TI provided API.); 2=TWO (Internal. Only to be used through TI provided API.); 1=DEM_OUT_WORD (Internal. Only to be used through TI provided API.); 0=SW5 (Internal. Only to be used through TI provided API.)
  [9:8] GPO4 rw — Internal. Only to be used through TI provided API.
    3=THREE (Internal. Only to be used through TI provided API.); 2=TWO (Internal. Only to be used through TI provided API.); 1=CORR_PEAK_C (Internal. Only to be used through TI provided API.); 0=SW4 (Internal. Only to be used through TI provided API.)
  [7:6] GPO3 rw — Internal. Only to be used through TI provided API.
    3=THREE (Internal. Only to be used through TI provided API.); 2=TWO (Internal. Only to be used through TI provided API.); 1=CORR_PEAK_B (Internal. Only to be used through TI provided API.); 0=SW3 (Internal. Only to be used through TI provided API.)
  [5:4] GPO2 rw — Internal. Only to be used through TI provided API.
    3=THREE (Internal. Only to be used through TI provided API.); 2=TWO (Internal. Only to be used through TI provided API.); 1=CORR_PEAK_A (Internal. Only to be used through TI provided API.); 0=SW2 (Internal. Only to be used through TI provided API.)
  [3:2] GPO1 rw — Internal. Only to be used through TI provided API.
    3=THREE (Internal. Only to be used through TI provided API.); 2=TWO (Internal. Only to be used through TI provided API.); 1=HWCLK1 (Internal. Only to be used through TI provided API.); 0=SW1 (Internal. Only to be used through TI provided API.)
  [1:0] GPO0 rw — Internal. Only to be used through TI provided API.
    3=THREE (Internal. Only to be used through TI provided API.); 2=LOOPBACK (Internal. Only to be used through TI provided API.); 1=HWCLK0 (Internal. Only to be used through TI provided API.); 0=SW0 (Internal. Only to be used through TI provided API.)
0x24C GPOCTRL1 — Internal. Only to be used through TI provided API.
  [31:16] RESERVED16 ro — Internal. Only to be used through TI provided API.
  [15:14] HWCLKSTRETCH rw — Internal. Only to be used through TI provided API.
    values as DEMFEXB0.OUT2PASSTHROUGH
  [13:11] HWCLKMUX1 rw — Internal. Only to be used through TI provided API.
    values as DEMFEXB0.OUT2PASSTHROUGH
  [10:8] HWCLKMUX0 rw — Internal. Only to be used through TI provided API.
    values as DEMFEXB0.OUT2PASSTHROUGH
  [7:0] SW rw — Internal. Only to be used through TI provided API.
    values as DEMFEXB0.OUT2PASSTHROUGH
0x250 RFERSSI ro — Internal. Only to be used through TI provided API.
  [31:8] RESERVED8 — Internal. Only to be used through TI provided API.
  [7:0] VAL — Internal. Only to be used through TI provided API.
    values as DEMIQMC0.GAINFACTOR
0x254 RFEMAXRSSI ro — Internal. Only to be used through TI provided API.
  fields as RFERSSI
0x258 RFEDBGAIN ro — Internal. Only to be used through TI provided API.
  fields as RFERSSI
0x25C SYNC0 ro — Internal. Only to be used through TI provided API.
  [31:16] RESERVED16 — Internal. Only to be used through TI provided API.
  [15:0] SWA15C0 — Internal. Only to be used through TI provided API.
    values as SPARE0.VAL
0x260 SYNC1 ro — Internal. Only to be used through TI provided API.
  [31:16] RESERVED16 — Internal. Only to be used through TI provided API.
  [15:0] SWA31C16 — Internal. Only to be used through TI provided API.
    values as SPARE0.VAL
0x264 SYNC2 ro — Internal. Only to be used through TI provided API.
  [31:16] RESERVED16 — Internal. Only to be used through TI provided API.
  [15:0] SWB15C0 — Internal. Only to be used through TI provided API.
    values as SPARE0.VAL
0x268 SYNC3 ro — Internal. Only to be used through TI provided API.
  [31:16] RESERVED16 — Internal. Only to be used through TI provided API.
  [15:0] SWB31C16 — Internal. Only to be used through TI provided API.
    values as SPARE0.VAL
0x354 STRB2 — Internal. Only to be used through TI provided API.
  [31:6] RESERVED6 ro — Internal. Only to be used through TI provided API.
  [5] C1BECOPY2 wo — Internal. Only to be used through TI provided API.
    values as DEMFEXB0.OUT2PASSTHROUGH
  [4] C1BEPEAKG wo — Internal. Only to be used through TI provided API.
    values as DEMFEXB0.OUT2PASSTHROUGH
  [3] C1BEPEAKDE wo — Internal. Only to be used through TI provided API.
    values as DEMFEXB0.OUT2PASSTHROUGH
  [2] C1BEPEAKF wo — Internal. Only to be used through TI provided API.
    values as DEMFEXB0.OUT2PASSTHROUGH
  [1] C1BEPEAKE wo — Internal. Only to be used through TI provided API.
    values as DEMFEXB0.OUT2PASSTHROUGH
  [0] C1BEPEAKD wo — Internal. Only to be used through TI provided API.
    values as DEMFEXB0.OUT2PASSTHROUGH
